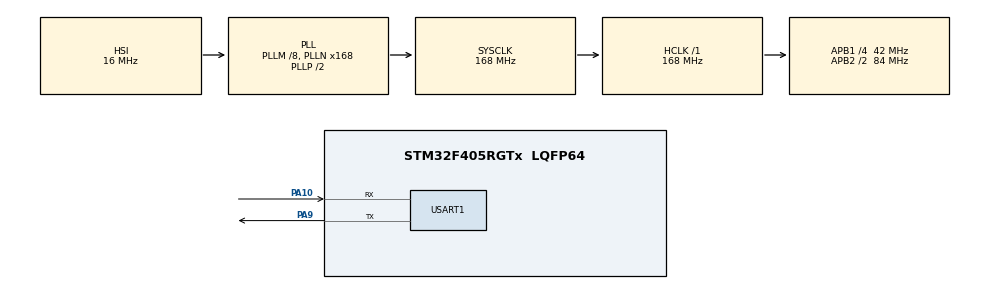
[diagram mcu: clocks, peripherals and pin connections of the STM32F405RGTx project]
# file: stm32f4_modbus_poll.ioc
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Mcu.Family=STM32F4
Mcu.Name=STM32F405RGTx
Mcu.Package=LQFP64
NVIC.PriorityGroup=NVIC_PRIORITYGROUP_4
NVIC.USART1_IRQn=true\:0\:0\:false\:false\:true\:true\:true\:true
PA10.Mode=Asynchronous
PA10.Signal=USART1_RX
PA13.Mode=Serial_Wire
PA13.Signal=SYS_JTMS-SWDIO
PA14.Mode=Serial_Wire
PA14.Signal=SYS_JTCK-SWCLK
PA9.Mode=Asynchronous
PA9.Signal=USART1_TX
PH0-OSC_IN.Mode=HSE-External-Oscillator
PH0-OSC_IN.Signal=RCC_OSC_IN
PH1-OSC_OUT.Mode=HSE-External-Oscillator
PH1-OSC_OUT.Signal=RCC_OSC_OUT
ProjectManager.HeapSize=0x200
ProjectManager.StackSize=0x400
ProjectManager.TargetToolchain=MDK-ARM V5.32
RCC.48MHZClocksFreq_Value=84000000
RCC.AHBFreq_Value=168000000
RCC.APB1CLKDivider=RCC_HCLK_DIV4
RCC.APB1Freq_Value=42000000
RCC.APB1TimFreq_Value=84000000
RCC.APB2CLKDivider=RCC_HCLK_DIV2
RCC.APB2Freq_Value=84000000
RCC.APB2TimFreq_Value=168000000
RCC.CortexFreq_Value=168000000
RCC.HCLKFreq_Value=168000000
RCC.HSE_VALUE=25000000
RCC.HSI_VALUE=16000000
RCC.LSE_VALUE=32768
RCC.PLLM=8
RCC.PLLN=168
RCC.SYSCLKFreq_VALUE=168000000
RCC.SYSCLKSource=RCC_SYSCLKSOURCE_PLLCLK
RCC.VCOOutputFreq_Value=336000000
USART1.VirtualMode=VM_ASYNC
board=custom

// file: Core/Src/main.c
/* USER CODE BEGIN Header */
/**
  ******************************************************************************
  * @file           : main.c
  * @brief          : Main program body
  ******************************************************************************
  * @attention
  *
  * Copyright (c) 2022 STMicroelectronics.
  * All rights reserved.
  *
  * This software is licensed under terms that can be found in the LICENSE file
  * in the root directory of this software component.
  * If no LICENSE file comes with this software, it is provided AS-IS.
  *
  ******************************************************************************
  */
	/*
	Modbus主机例程，配置时仅需配置USART1,并打开串口中断
	注意在stm32f4xx_it.c完善中断函数USART1_IRQHandler，并main函数使能中断
	所有功能都在 modbus_master.c 文件，如读Input Registers功能
	使用不同芯片，不同串口时修改bsp_board.h
	*/
/* USER CODE END Header */
#include "main.h"

/* USER CODE BEGIN Includes */
#include "modbus_master.h"//包含modbus主机头文件
/* USER CODE END Includes */

 UART_HandleTypeDef huart1;

/* USER CODE BEGIN PV */
uint8_t result;
uint16_t Input_Result[2];
/* USER CODE END PV */

void SystemClock_Config(void);
static void MX_GPIO_Init(void);
static void MX_USART1_UART_Init(void);

int main(void)
{

  /* MCU Configuration--------------------------------------------------------*/

  /* Reset of all peripherals, Initializes the Flash interface and the Systick. */
  HAL_Init();

  /* Configure the system clock */
  SystemClock_Config();

  /* Initialize all configured peripherals */
  MX_GPIO_Init();
  MX_USART1_UART_Init();
  /* USER CODE BEGIN 2 */
	ModbusMaster_begin();//初始化Modbus
	__HAL_UART_ENABLE_IT(&stm32_huart,UART_IT_RXNE);//使能串口中断
  /* USER CODE END 2 */

  /* Infinite loop */
  while (1)
  {

    /* USER CODE BEGIN 3 */
		result = ModbusMaster_readInputRegisters(0x01,0x0,2);//读连续两个寄存器地址，ID,地址，数量
		if(result == 0x00)
		{
			Input_Result[0] = ModbusMaster_getResponseBuffer(0x00);
			Input_Result[1] = ModbusMaster_getResponseBuffer(0x01);
		}
		HAL_Delay(1000);
//		/*例子函数*/
//	/*第0个寄存器，写入2的数据*/
//			ModbusMaster_setTransmitBuffer(0,1280);
//	/*第1个寄存器，写入100的数据*/
//			ModbusMaster_setTransmitBuffer(1,2560);
//	/*从机地址为0x01的设备，从十六进制的2000寄存器开始，顺序写入两个数据寄存器*/
//			ModbusMaster_writeMultipleRegisters(0x01,0x00,2);
//	/*modbus通信协议 超个3.5个字节通信的时间，则代表一次数据发送结束*/
//			HAL_Delay(500);
//	/*与上述同理*/
			ModbusMaster_writeSingleCoil(0x01,0x02,1);//写单个线圈，ID,地址，状态
			ModbusMaster_writeSingleCoil(0x01,0x03,0);
			HAL_Delay(500);
			ModbusMaster_writeSingleCoil(0x01,0x02,0);
			ModbusMaster_writeSingleCoil(0x01,0x03,1);
			HAL_Delay(500);
  }
  /* USER CODE END 3 */
}

void SystemClock_Config(void)
{
  RCC_OscInitTypeDef RCC_OscInitStruct = {0};
  RCC_ClkInitTypeDef RCC_ClkInitStruct = {0};

  /** Configure the main internal regulator output voltage
  */
  __HAL_RCC_PWR_CLK_ENABLE();
  __HAL_PWR_VOLTAGESCALING_CONFIG(PWR_REGULATOR_VOLTAGE_SCALE1);

  /** Initializes the RCC Oscillators according to the specified parameters
  * in the RCC_OscInitTypeDef structure.
  */
  RCC_OscInitStruct.OscillatorType = RCC_OSCILLATORTYPE_HSI;
  RCC_OscInitStruct.HSIState = RCC_HSI_ON;
  RCC_OscInitStruct.HSICalibrationValue = RCC_HSICALIBRATION_DEFAULT;
  RCC_OscInitStruct.PLL.PLLState = RCC_PLL_ON;
  RCC_OscInitStruct.PLL.PLLSource = RCC_PLLSOURCE_HSI;
  RCC_OscInitStruct.PLL.PLLM = 8;
  RCC_OscInitStruct.PLL.PLLN = 168;
  RCC_OscInitStruct.PLL.PLLP = RCC_PLLP_DIV2;
  RCC_OscInitStruct.PLL.PLLQ = 4;
  if (HAL_RCC_OscConfig(&RCC_OscInitStruct) != HAL_OK)
  {
    Error_Handler();
  }

  /** Initializes the CPU, AHB and APB buses clocks
  */
  RCC_ClkInitStruct.ClockType = RCC_CLOCKTYPE_HCLK|RCC_CLOCKTYPE_SYSCLK
                              |RCC_CLOCKTYPE_PCLK1|RCC_CLOCKTYPE_PCLK2;
  RCC_ClkInitStruct.SYSCLKSource = RCC_SYSCLKSOURCE_PLLCLK;
  RCC_ClkInitStruct.AHBCLKDivider = RCC_SYSCLK_DIV1;
  RCC_ClkInitStruct.APB1CLKDivider = RCC_HCLK_DIV4;
  RCC_ClkInitStruct.APB2CLKDivider = RCC_HCLK_DIV2;

  if (HAL_RCC_ClockConfig(&RCC_ClkInitStruct, FLASH_LATENCY_5) != HAL_OK)
  {
    Error_Handler();
  }
}

static void MX_USART1_UART_Init(void)
{

  huart1.Instance = USART1;
  huart1.Init.BaudRate = 115200;
  huart1.Init.WordLength = UART_WORDLENGTH_8B;
  huart1.Init.StopBits = UART_STOPBITS_1;
  huart1.Init.Parity = UART_PARITY_NONE;
  huart1.Init.Mode = UART_MODE_TX_RX;
  huart1.Init.HwFlowCtl = UART_HWCONTROL_NONE;
  huart1.Init.OverSampling = UART_OVERSAMPLING_16;
  if (HAL_UART_Init(&huart1) != HAL_OK)
  {
    Error_Handler();
  }

}

static void MX_GPIO_Init(void)
{

  /* GPIO Ports Clock Enable */
  __HAL_RCC_GPIOH_CLK_ENABLE();
  __HAL_RCC_GPIOA_CLK_ENABLE();

}

void Error_Handler(void)
{
  __disable_irq();
  while (1)
  {
  }
}
